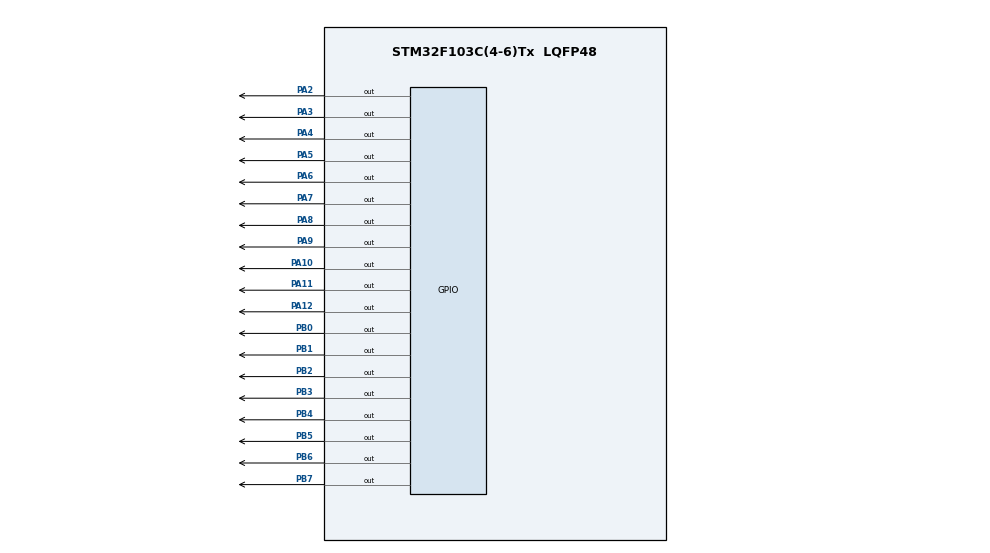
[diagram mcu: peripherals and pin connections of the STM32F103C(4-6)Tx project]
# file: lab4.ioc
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Mcu.Family=STM32F1
Mcu.Name=STM32F103C(4-6)Tx
Mcu.Package=LQFP48
NVIC.PriorityGroup=NVIC_PRIORITYGROUP_4
NVIC.TIM2_IRQn=true\:0\:0\:false\:false\:true\:true\:true
PA10.Signal=GPIO_Output
PA11.Signal=GPIO_Output
PA12.Signal=GPIO_Output
PA2.Signal=GPIO_Output
PA3.Signal=GPIO_Output
PA4.Signal=GPIO_Output
PA5.Signal=GPIO_Output
PA6.Signal=GPIO_Output
PA7.Signal=GPIO_Output
PA8.Signal=GPIO_Output
PA9.Signal=GPIO_Output
PB0.Signal=GPIO_Output
PB1.Signal=GPIO_Output
PB2.Signal=GPIO_Output
PB3.Signal=GPIO_Output
PB4.Signal=GPIO_Output
PB5.Signal=GPIO_Output
PB6.Signal=GPIO_Output
PB7.Signal=GPIO_Output
PC14-OSC32_IN.Mode=LSE-External-Oscillator
PC14-OSC32_IN.Signal=RCC_OSC32_IN
PC15-OSC32_OUT.Mode=LSE-External-Oscillator
PC15-OSC32_OUT.Signal=RCC_OSC32_OUT
PD0-OSC_IN.Mode=HSE-External-Oscillator
PD0-OSC_IN.Signal=RCC_OSC_IN
PD1-OSC_OUT.Mode=HSE-External-Oscillator
PD1-OSC_OUT.Signal=RCC_OSC_OUT
ProjectManager.HeapSize=0x200
ProjectManager.StackSize=0x400
ProjectManager.TargetToolchain=STM32CubeIDE
RCC.APB1Freq_Value=8000000
RCC.APB2Freq_Value=8000000
TIM2.Period=9
TIM2.Prescaler=7999
VP_IWDG_VS_IWDG.Mode=IWDG_Activate
VP_SYS_VS_ND.Mode=No_Debug
VP_TIM2_VS_ClockSourceINT.Mode=Internal
board=custom

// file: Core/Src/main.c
/* USER CODE BEGIN Header */
/**
  ******************************************************************************
  * @file           : main.c
  * @brief          : Main program body
  ******************************************************************************
  * @attention
  *
  * <h2><center>&copy; Copyright (c) 2021 STMicroelectronics.
  * All rights reserved.</center></h2>
  *
  * This software component is licensed by ST under BSD 3-Clause license,
  * the "License"; You may not use this file except in compliance with the
  * License. You may obtain a copy of the License at:
  *                        opensource.org/licenses/BSD-3-Clause
  *
  ******************************************************************************
  */
/* USER CODE END Header */
#include "main.h"

/* USER CODE BEGIN Includes */
#include "task.h"
#include "scheduler.h"
/* USER CODE END Includes */

IWDG_HandleTypeDef hiwdg;

TIM_HandleTypeDef htim2;

void SystemClock_Config(void);
static void MX_GPIO_Init(void);
static void MX_TIM2_Init(void);
static void MX_IWDG_Init(void);

/* USER CODE BEGIN 0 */
/*
IWDG_HandleTypeDef hiwdg;
static uint32_t counter_for_watchdog = 0;

void MX_IWDG_Init(void){
  hiwdg.Instance = IWDG;
  hiwdg.Init.Prescaler = IWDG_PRESCALER_32;
  hiwdg.Init.Reload = 4095;
  if (HAL_IWDG_Init(&hiwdg) != HAL_OK) {
    Error_Handler();
  }
}
void Watchdog_Refresh(void){
	HAL_IWDG_Refresh(&hiwdg);
}
unsigned char Is_Watchdog_Reset(void){
	if(counter_for_watchdog > 3){
		return 1;
	}
	return 0;
}
void Watchdog_Counting(void){
	counter_for_watchdog++;
}

void Reset_Watchdog_Counting(void){
	counter_for_watchdog = 0;
}
*/
/* USER CODE END 0 */

int main(void)
{

  /* MCU Configuration--------------------------------------------------------*/

  /* Reset of all peripherals, Initializes the Flash interface and the Systick. */
  HAL_Init();

  /* Configure the system clock */
  SystemClock_Config();

  /* Initialize all configured peripherals */
  MX_GPIO_Init();
  MX_TIM2_Init();
  MX_IWDG_Init();
  /* USER CODE BEGIN 2 */
  SCH_Init ();
  SCH_Add_Task (toogle_led2 ,0,50);
  SCH_Add_Task (toogle_led3 ,0,100);
  SCH_Add_Task (toogle_led4 ,0,150);
  SCH_Add_Task (toogle_led5 ,0,200);
  SCH_Add_Task (toogle_led6 ,0,250);
  SCH_Add_Task (toogle_led7 ,0,1600);
  SCH_Delete_Task(7) ;
  /* USER CODE END 2 */

  /* Infinite loop */
  while (1)
  {
	  //HAL_IWDG_Refresh(&hiwdg);
	  SCH_Dispatch_Tasks();
    /* USER CODE BEGIN 3 */
  }
  void HAL_TIM_PeriodElapsedCallback(TIM_HandleTypeDef *htim){
  	SCH_Update();
  }
  /* USER CODE END 3 */
}

void SystemClock_Config(void)
{
  RCC_OscInitTypeDef RCC_OscInitStruct = {0};
  RCC_ClkInitTypeDef RCC_ClkInitStruct = {0};

  /** Initializes the RCC Oscillators according to the specified parameters
  * in the RCC_OscInitTypeDef structure.
  */
  RCC_OscInitStruct.OscillatorType = RCC_OSCILLATORTYPE_HSI|RCC_OSCILLATORTYPE_LSI;
  RCC_OscInitStruct.HSIState = RCC_HSI_ON;
  RCC_OscInitStruct.HSICalibrationValue = RCC_HSICALIBRATION_DEFAULT;
  RCC_OscInitStruct.LSIState = RCC_LSI_ON;
  RCC_OscInitStruct.PLL.PLLState = RCC_PLL_NONE;
  if (HAL_RCC_OscConfig(&RCC_OscInitStruct) != HAL_OK)
  {
    Error_Handler();
  }
  /** Initializes the CPU, AHB and APB buses clocks
  */
  RCC_ClkInitStruct.ClockType = RCC_CLOCKTYPE_HCLK|RCC_CLOCKTYPE_SYSCLK
                              |RCC_CLOCKTYPE_PCLK1|RCC_CLOCKTYPE_PCLK2;
  RCC_ClkInitStruct.SYSCLKSource = RCC_SYSCLKSOURCE_HSI;
  RCC_ClkInitStruct.AHBCLKDivider = RCC_SYSCLK_DIV1;
  RCC_ClkInitStruct.APB1CLKDivider = RCC_HCLK_DIV1;
  RCC_ClkInitStruct.APB2CLKDivider = RCC_HCLK_DIV1;

  if (HAL_RCC_ClockConfig(&RCC_ClkInitStruct, FLASH_LATENCY_0) != HAL_OK)
  {
    Error_Handler();
  }
}

static void MX_IWDG_Init(void)
{

  hiwdg.Instance = IWDG;
  hiwdg.Init.Prescaler = IWDG_PRESCALER_4;
  hiwdg.Init.Reload = 4095;
  if (HAL_IWDG_Init(&hiwdg) != HAL_OK)
  {
    Error_Handler();
  }

}

static void MX_TIM2_Init(void)
{

  TIM_ClockConfigTypeDef sClockSourceConfig = {0};
  TIM_MasterConfigTypeDef sMasterConfig = {0};

  htim2.Instance = TIM2;
  htim2.Init.Prescaler = 7999;
  htim2.Init.CounterMode = TIM_COUNTERMODE_UP;
  htim2.Init.Period = 9;
  htim2.Init.ClockDivision = TIM_CLOCKDIVISION_DIV1;
  htim2.Init.AutoReloadPreload = TIM_AUTORELOAD_PRELOAD_DISABLE;
  if (HAL_TIM_Base_Init(&htim2) != HAL_OK)
  {
    Error_Handler();
  }
  sClockSourceConfig.ClockSource = TIM_CLOCKSOURCE_INTERNAL;
  if (HAL_TIM_ConfigClockSource(&htim2, &sClockSourceConfig) != HAL_OK)
  {
    Error_Handler();
  }
  sMasterConfig.MasterOutputTrigger = TIM_TRGO_RESET;
  sMasterConfig.MasterSlaveMode = TIM_MASTERSLAVEMODE_DISABLE;
  if (HAL_TIMEx_MasterConfigSynchronization(&htim2, &sMasterConfig) != HAL_OK)
  {
    Error_Handler();
  }

}

static void MX_GPIO_Init(void)
{
  GPIO_InitTypeDef GPIO_InitStruct = {0};

  /* GPIO Ports Clock Enable */
  __HAL_RCC_GPIOC_CLK_ENABLE();
  __HAL_RCC_GPIOD_CLK_ENABLE();
  __HAL_RCC_GPIOA_CLK_ENABLE();
  __HAL_RCC_GPIOB_CLK_ENABLE();

  /*Configure GPIO pin Output Level */
  HAL_GPIO_WritePin(GPIOA, GPIO_PIN_2|GPIO_PIN_3|GPIO_PIN_4|GPIO_PIN_5
                          |GPIO_PIN_6|GPIO_PIN_7|GPIO_PIN_8|GPIO_PIN_9
                          |GPIO_PIN_10|GPIO_PIN_11|GPIO_PIN_12, GPIO_PIN_RESET);

  /*Configure GPIO pin Output Level */
  HAL_GPIO_WritePin(GPIOB, GPIO_PIN_0|GPIO_PIN_1|GPIO_PIN_2|GPIO_PIN_3
                          |GPIO_PIN_4|GPIO_PIN_5|GPIO_PIN_6|GPIO_PIN_7, GPIO_PIN_RESET);

  /*Configure GPIO pins : PA2 PA3 PA4 PA5
                           PA6 PA7 PA8 PA9
                           PA10 PA11 PA12 */
  GPIO_InitStruct.Pin = GPIO_PIN_2|GPIO_PIN_3|GPIO_PIN_4|GPIO_PIN_5
                          |GPIO_PIN_6|GPIO_PIN_7|GPIO_PIN_8|GPIO_PIN_9
                          |GPIO_PIN_10|GPIO_PIN_11|GPIO_PIN_12;
  GPIO_InitStruct.Mode = GPIO_MODE_OUTPUT_PP;
  GPIO_InitStruct.Pull = GPIO_NOPULL;
  GPIO_InitStruct.Speed = GPIO_SPEED_FREQ_LOW;
  HAL_GPIO_Init(GPIOA, &GPIO_InitStruct);

  /*Configure GPIO pins : PB0 PB1 PB2 PB3
                           PB4 PB5 PB6 PB7 */
  GPIO_InitStruct.Pin = GPIO_PIN_0|GPIO_PIN_1|GPIO_PIN_2|GPIO_PIN_3
                          |GPIO_PIN_4|GPIO_PIN_5|GPIO_PIN_6|GPIO_PIN_7;
  GPIO_InitStruct.Mode = GPIO_MODE_OUTPUT_PP;
  GPIO_InitStruct.Pull = GPIO_NOPULL;
  GPIO_InitStruct.Speed = GPIO_SPEED_FREQ_LOW;
  HAL_GPIO_Init(GPIOB, &GPIO_InitStruct);

}

void Error_Handler(void)
{
  __disable_irq();
  while (1)
  {
  }
}

/************************ (C) COPYRIGHT STMicroelectronics *****END OF FILE****/
